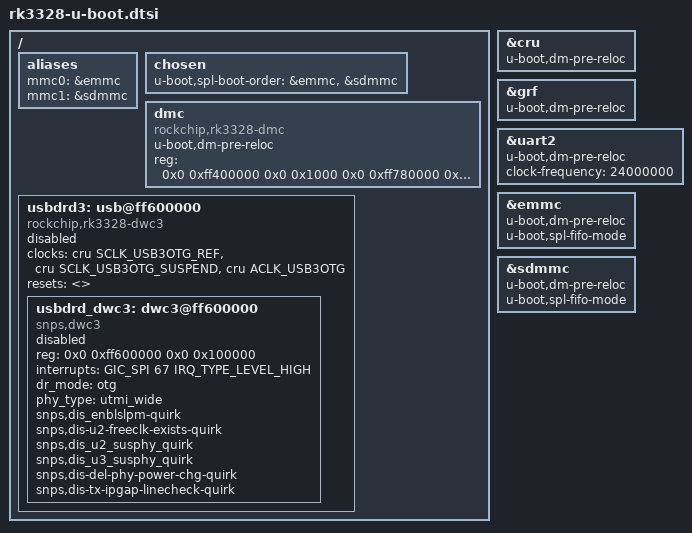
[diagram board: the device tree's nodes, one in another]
// SPDX-License-Identifier: GPL-2.0+
/*
 * (C) Copyright 2019 Rockchip Electronics Co., Ltd
 */

/ {
	aliases {
		mmc0 = &emmc;
		mmc1 = &sdmmc;
	};

	chosen {
		u-boot,spl-boot-order = &emmc, &sdmmc;
	};

	dmc: dmc {
		u-boot,dm-pre-reloc;
		compatible = "rockchip,rk3328-dmc";
		reg = <0x0 0xff400000 0x0 0x1000
		       0x0 0xff780000 0x0 0x3000
		       0x0 0xff100000 0x0 0x1000
		       0x0 0xff440000 0x0 0x1000
		       0x0 0xff720000 0x0 0x1000
		       0x0 0xff798000 0x0 0x1000>;
	};

	usbdrd3: usb@ff600000 {
		compatible = "rockchip,rk3328-dwc3", "rockchip,rk3399-dwc3";
		clocks = <&cru SCLK_USB3OTG_REF>, <&cru SCLK_USB3OTG_SUSPEND>,
			 <&cru ACLK_USB3OTG>;
		clock-names = "ref_clk", "suspend_clk",
			      "bus_clk";
		resets = <>;
		reset-names = <>;
		#address-cells = <2>;
		#size-cells = <2>;
		ranges;
		status = "disabled";

		usbdrd_dwc3: dwc3@ff600000 {
			compatible = "snps,dwc3";
			reg = <0x0 0xff600000 0x0 0x100000>;
			interrupts = <GIC_SPI 67 IRQ_TYPE_LEVEL_HIGH>;
			dr_mode = "otg";
			phy_type = "utmi_wide";
			snps,dis_enblslpm-quirk;
			snps,dis-u2-freeclk-exists-quirk;
			snps,dis_u2_susphy_quirk;
			snps,dis_u3_susphy_quirk;
			snps,dis-del-phy-power-chg-quirk;
			snps,dis-tx-ipgap-linecheck-quirk;
			status = "disabled";
		};
	};
};

&cru {
	u-boot,dm-pre-reloc;
};

&grf {
	u-boot,dm-pre-reloc;
};

&uart2 {
	u-boot,dm-pre-reloc;
	clock-frequency = <24000000>;
};

&emmc {
	u-boot,dm-pre-reloc;

	/* mmc to sram can't do dma, prevent aborts transfering TF-A parts */
	u-boot,spl-fifo-mode;
};

&sdmmc {
	u-boot,dm-pre-reloc;

	/* mmc to sram can't do dma, prevent aborts transfering TF-A parts */
	u-boot,spl-fifo-mode;
};
